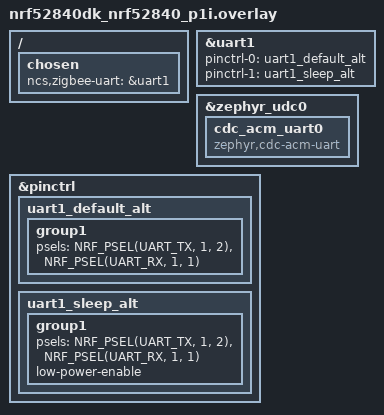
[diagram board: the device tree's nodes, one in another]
/*
 * Copyright (c) 2025 Nordic Semiconductor ASA
 *
 * SPDX-License-Identifier: LicenseRef-Nordic-5-Clause
 */

&uart1 {
	pinctrl-0 = <&uart1_default_alt>;
	pinctrl-1 = <&uart1_sleep_alt>;
	pinctrl-names = "default", "sleep";
	status = "okay";
};

&zephyr_udc0 {
	cdc_acm_uart0: cdc_acm_uart0 {
		compatible = "zephyr,cdc-acm-uart";
	};
};

&pinctrl {
	uart1_default_alt: uart1_default_alt {
		group1 {
			psels = <NRF_PSEL(UART_TX, 1, 2)>,
				<NRF_PSEL(UART_RX, 1, 1)>;
		};
	};

	uart1_sleep_alt: uart1_sleep_alt {
		group1 {
			psels = <NRF_PSEL(UART_TX, 1, 2)>,
				<NRF_PSEL(UART_RX, 1, 1)>;
			low-power-enable;
		};
	};
};

/ {
	chosen {
		ncs,zigbee-uart = &uart1;
	};
};
